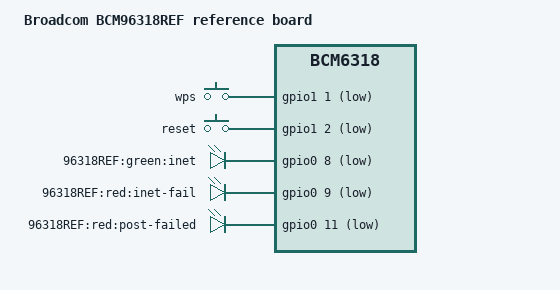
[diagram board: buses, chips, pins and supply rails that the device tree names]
/dts-v1/;

#include "bcm6318.dtsi"

#include <dt-bindings/input/input.h>

/ {
	model = "Broadcom BCM96318REF reference board";
	compatible = "brcm,bcm96318ref", "brcm,bcm6318";

	chosen {
		bootargs = "root=/dev/mtdblock2 rootfstype=squashfs,jffs2 noinitrd console=ttyS0,115200";
	};

	gpio-keys-polled {
		compatible = "gpio-keys-polled";
		#address-cells = <1>;
		#size-cells = <0>;
		poll-interval = <20>;
		debounce-interval = <60>;

		wps {
			label = "wps";
			gpios = <&gpio1 1 1>;
			linux,code = <KEY_WPS_BUTTON>;
		};

		reset {
			label = "reset";
			gpios = <&gpio1 2 1>;
			linux,code = <KEY_RESTART>;
		};
        };

	gpio-leds {
		compatible = "gpio-leds";

		inet {
			label = "96318REF:green:inet";
			gpios = <&gpio0 8 1>;
		};

		inet_fail {
			label = "96318REF:red:inet-fail";
			gpios = <&gpio0 9 1>;
		};

		post_failed {
			label = "96318REF:red:post-failed";
			gpios = <&gpio0 11 1>;
		};
	};
};
